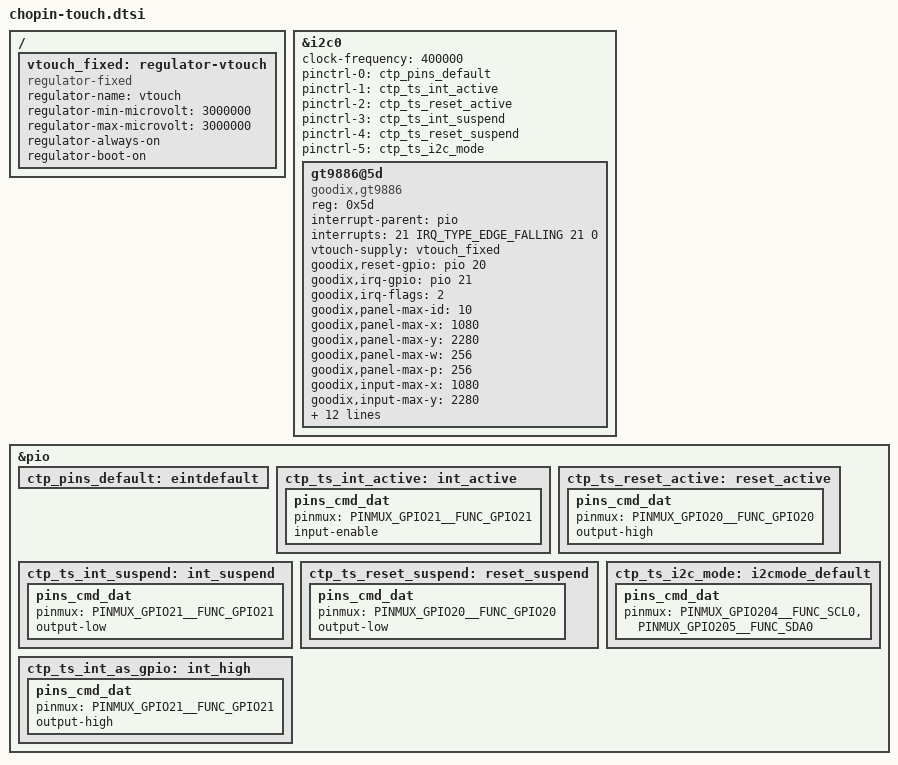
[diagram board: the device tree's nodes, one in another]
/* SPDX-License-Identifier: GPL-2.0 */
/*
 * chopin (Redmi Note 10 Pro / MT6891Z) touch configuration
 * Target: Linux 5.10.233 + MediaTek mt6893 (Hwhmi/kernel-mtk-6893 @ mt6893-5.10)
 *
 * 数据来源：4.14 原厂 arch/arm64/boot/dts/mediatek/cust_mt6893_touch.dtsi
 *   - I2C 地址   : 0x5d  (i2c0, 400kHz)
 *   - reset GPIO : 20
 *   - irq   GPIO : 21  (falling edge)
 *   - 触摸区域   : 1080 x 2280  (注意：不是 2340，5.10 参考板是 2340)
 *   - 固件版本   : 6893v01
 *
 * 与 5.10 自带 cust_mt6893_touch_gt9886_1080_2340.dtsi 的差异：
 *   1. panel-max-y / input-max-y : 2340 -> 2280
 *   2. firmware/config version   : 6885af/90hz6885 -> 6893v01
 *   3. 补回第二颗 gt9896s (SPI)  —— 可选，第一轮可不要
 *
 * 用法：在板级 dts 里 #include "chopin-touch.dtsi"
 */

/* ========== 供电：bring-up 阶段用 fixed regulator 绕过 PMIC 依赖 ========== */
/* 若确认 mt6359p.dtsi 里有 VTP LDO，可改用 &mt6359p_vtp_reg 之类 */
/ {
	vtouch_fixed: regulator-vtouch {
		compatible = "regulator-fixed";
		regulator-name = "vtouch";
		regulator-min-microvolt = <3000000>;
		regulator-max-microvolt = <3000000>;
		regulator-always-on;
		regulator-boot-on;
	};
};

/* ========== I2C0 + GT9886 ========== */
&i2c0 {
	clock-frequency = <400000>;
	pinctrl-names = "default", "ts_int_active",
		"ts_reset_active", "ts_int_suspend",
		"ts_reset_suspend", "ts_i2c_mode";
	pinctrl-0 = <&ctp_pins_default>;
	pinctrl-1 = <&ctp_ts_int_active>;
	pinctrl-2 = <&ctp_ts_reset_active>;
	pinctrl-3 = <&ctp_ts_int_suspend>;
	pinctrl-4 = <&ctp_ts_reset_suspend>;
	pinctrl-5 = <&ctp_ts_i2c_mode>;
	status = "okay";

	gt9886@5d {
		compatible = "goodix,gt9886";
		reg = <0x5d>;
		status = "okay";
		interrupt-parent = <&pio>;
		interrupts = <21 IRQ_TYPE_EDGE_FALLING 21 0>;
		vtouch-supply = <&vtouch_fixed>;
		goodix,reset-gpio = <&pio 20 0x0>;
		goodix,irq-gpio = <&pio 21 0x0>;
		goodix,irq-flags = <2>;		/* 1:rising, 2:falling */
		goodix,panel-max-id = <10>;
		goodix,panel-max-x = <1080>;
		goodix,panel-max-y = <2280>;
		goodix,panel-max-w = <256>;
		goodix,panel-max-p = <256>;
		goodix,input-max-x = <1080>;
		goodix,input-max-y = <2280>;
		goodix,panel-key-map = <158 172 217>;	/* BACK, HOME, SEARCH */
		goodix,power-on-delay-us = <10000>;	/* 10ms */
		goodix,power-off-delay-us = <5000>;
		goodix,firmware-version = "6893v01";
		goodix,config-version = "6893v01";
		/* goodix,swap-axis; */
		/* goodix,x2x; */
		/* goodix,y2y; */
		goodix,pen-enable;
		goodix,key-of-pen = <331 332>;	/* BTN_STYLUS, BTN_STYLUS2 */
		tpd-filter-enable = <0>;
		tpd-filter-pixel-density = <161>;
		tpd-filter-custom-prameters = <0 0 0 0 0 0 0 0 0 0 0 0>;
		tpd-filter-custom-speed = <0 0 0>;
	};
};

/* ========== Pinctrl ========== */
&pio {
	ctp_pins_default: eintdefault {
	};

	ctp_ts_int_active: int_active {
		pins_cmd_dat {
			pinmux = <PINMUX_GPIO21__FUNC_GPIO21>;
			input-enable;
		};
	};

	ctp_ts_reset_active: reset_active {
		pins_cmd_dat {
			pinmux = <PINMUX_GPIO20__FUNC_GPIO20>;
			output-high;
		};
	};

	ctp_ts_int_suspend: int_suspend {
		pins_cmd_dat {
			pinmux = <PINMUX_GPIO21__FUNC_GPIO21>;
			output-low;
		};
	};

	ctp_ts_reset_suspend: reset_suspend {
		pins_cmd_dat {
			pinmux = <PINMUX_GPIO20__FUNC_GPIO20>;
			output-low;
		};
	};

	ctp_ts_i2c_mode: i2cmode_default {
		pins_cmd_dat {
			pinmux = <PINMUX_GPIO204__FUNC_SCL0>,
				<PINMUX_GPIO205__FUNC_SDA0>;
		};
	};

	ctp_ts_int_as_gpio: int_high {
		pins_cmd_dat {
			pinmux = <PINMUX_GPIO21__FUNC_GPIO21>;
			output-high;
		};
	};
};

/* ==========================================================================
 * 可选：第二颗触控 GT9896S（SPI4）
 *
 * chopin 原厂配置里除了 I2C 的 GT9886，还有一颗 SPI 接口的 GT9896S。
 * 通常机器只实际贴其中一颗（按批次/供应商）。第一轮 bring-up 建议先注释掉，
 * 等 GT9886 跑通、确认 /proc/bus/input/devices 没有设备后，再启用这一段。
 * ==========================================================================
 */
/*
&spi4 {
	status = "okay";
	#address-cells = <1>;
	#size-cells = <0>;
	pinctrl-names = "default", "gt9896s_int_active",
		"gt9896s_reset_active", "gt9896s_int_suspend",
		"gt9896s_reset_suspend", "gt9896s_spi_mode";
	pinctrl-0 = <&ctp_gt9896s_pins_default>;
	pinctrl-1 = <&ctp_gt9896s_int_active>;
	pinctrl-2 = <&ctp_gt9896s_reset_active>;
	pinctrl-3 = <&ctp_gt9896s_int_suspend>;
	pinctrl-4 = <&ctp_gt9896s_reset_suspend>;
	pinctrl-5 = <&ctp_gt9896s_spi_mode>;

	gt9896s@0 {
		compatible = "goodix,gt9896s";
		reg = <0>;
		spi-max-frequency = <1000000>;
		goodix,avdd-name = "vtouch";
		vtouch-supply = <&vtouch_fixed>;
		goodix,reset-gpio = <&pio 20 0x0>;
		goodix,irq-gpio = <&pio 21 0x0>;
		goodix,irq-flags = <2>;
		goodix,panel-max-id = <10>;
		goodix,panel-max-x = <1080>;
		goodix,panel-max-y = <2300>;
		goodix,panel-max-w = <256>;
		goodix,panel-max-p = <256>;
		goodix,input-max-x = <1080>;
		goodix,input-max-y = <2300>;
		goodix,firmware-version = "6893v02";
		goodix,config-version = "6893v02";
		goodix,power-on-delay-us = <10000>;
		goodix,power-off-delay-us = <5000>;
		goodix,pen-enable;
		tpd-filter-enable = <0>;
		tpd-filter-pixel-density = <161>;
	};
};

&pio {
	ctp_gt9896s_pins_default: pins_default {
	};
	ctp_gt9896s_int_active: int1_active {
		pins_cmd_dat {
			pinmux = <PINMUX_GPIO21__FUNC_GPIO21>;
			input-enable;
		};
	};
	ctp_gt9896s_reset_active: reset1_active {
		pins_cmd_dat {
			pinmux = <PINMUX_GPIO20__FUNC_GPIO20>;
			output-high;
		};
	};
	ctp_gt9896s_spi_mode: spimode_default {
		pins_cmd_dat {
			pinmux = <PINMUX_GPIO18__FUNC_SPI4_C_MI>,
				<PINMUX_GPIO19__FUNC_SPI4_C_MO>,
				<PINMUX_GPIO204__FUNC_SPI4_C_CLK>,
				<PINMUX_GPIO205__FUNC_SPI4_C_CSB>;
			drive-strength = <2>;
		};
	};
};
*/
